# STM32C031 register map
File version: 1.4
CPU: CM0 r0p0, little endian, MPU, FPU, 4 interrupt priority bits
Registers are 32-bit, read-write, reset 0x0 unless marked. A register's access mark holds for its fields unless they carry their own. Offsets are from the block's base; [hi:lo] are bit positions; 'fields as' and 'values as' point back to an identical list.

## TIM16 — General-purpose timers
Base 0x40014400
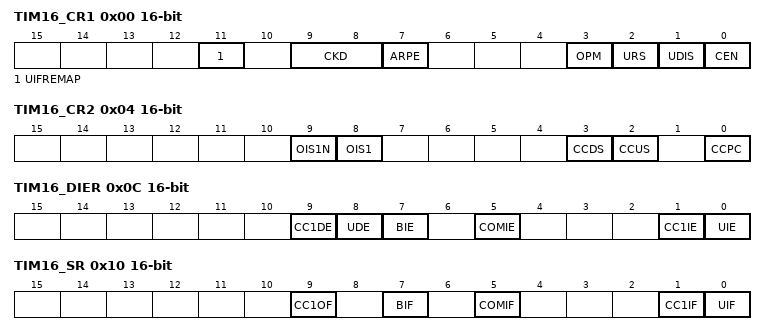
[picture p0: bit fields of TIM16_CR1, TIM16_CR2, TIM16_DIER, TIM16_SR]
0x00 TIM16_CR1 16-bit — TIM16 control register 1
  [11] UIFREMAP — UIF status bit remapping
    0=No remapping. UIF status bit is not copied to TIMx_CNT register bit 31.; 1=Remapping enabled. UIF status bit is copied to TIMx_CNT register bit 31.
  [9:8] CKD — Clock division This bit-field indicates the division ratio between the timer clock (CK_INT) frequency and the dead-time and sampling clock (tDTS)used by the dead-time generators and the digital filters (TIx),
    0=tDTS = tCK_INT; 1=tDTS = 2 * tCK_INT; 2=tDTS = 4 * tCK_INT; 3=Reserved, do not program this value
  [7] ARPE — Auto-reload preload enable
    0=TIMx_ARR register is not buffered; 1=TIMx_ARR register is buffered
  [3] OPM — One pulse mode
    0=Counter is not stopped at update event; 1=Counter stops counting at the next update event (clearing the bit CEN)
  [2] URS — Update request source This bit is set and cleared by software to select the UEV event sources. Counter overflow/underflow Setting the UG bit Update generation through the slave mode controller
    0=Any of the following events generate an update interrupt or DMA request if enabled. These events can be:; 1=Only counter overflow/underflow generates an update interrupt or DMA request if enabled
  [1] UDIS — Update disable This bit is set and cleared by software to enable/disable UEV event generation. Counter overflow/underflow Setting the UG bit Update generation through the slave mode controller Buffered registers are then loaded with their preload values.
    0=UEV enabled. The Update (UEV) event is generated by one of the following events:; 1=UEV disabled. The Update event is not generated, shadow registers keep their value (ARR, PSC, CCRx). However the counter and the prescaler are reinitialized if the UG bit is set or if a hardware reset is received from the slave mode controller.
  [0] CEN — Counter enable Note: External clock and gated mode can work only if the CEN bit has been previously set by software. However trigger mode can set the CEN bit automatically by hardware.
    0=Counter disabled; 1=Counter enabled
0x04 TIM16_CR2 16-bit — TIM16 control register 2
  [9] OIS1N — Output Idle state 1 (OC1N output) Note: This bit can not be modified as long as LOCK level 1, 2 or 3 has been programmed (LOCK bits in TIMx_BDTR register).
    0=OC1N=0 after a dead-time when MOE=0; 1=OC1N=1 after a dead-time when MOE=0
  [8] OIS1 — Output Idle state 1 (OC1 output) Note: This bit can not be modified as long as LOCK level 1, 2 or 3 has been programmed (LOCK bits in TIMx_BDTR register).
    0=OC1=0 (after a dead-time if OC1N is implemented) when MOE=0; 1=OC1=1 (after a dead-time if OC1N is implemented) when MOE=0
  [3] CCDS — Capture/compare DMA selection
    0=CCx DMA request sent when CCx event occurs; 1=CCx DMA requests sent when update event occurs
  [2] CCUS — Capture/compare control update selection Note: This bit acts only on channels that have a complementary output.
    0=When capture/compare control bits are preloaded (CCPC=1), they are updated by setting the COMG bit only; 1=When capture/compare control bits are preloaded (CCPC=1), they are updated by setting the COMG bit or when an rising edge occurs on TRGI
  [0] CCPC — Capture/compare preloaded control Note: This bit acts only on channels that have a complementary output.
    0=CCxE, CCxNE and OCxM bits are not preloaded; 1=CCxE, CCxNE and OCxM bits are preloaded, after having been written, they are updated only when COM bit is set
0x0C TIM16_DIER 16-bit — TIM16 DMA/interrupt enable register
  [9] CC1DE — Capture/Compare 1 DMA request enable
    0=CC1 DMA request disabled; 1=CC1 DMA request enabled
  [8] UDE — Update DMA request enable
    0=Update DMA request disabled; 1=Update DMA request enabled
  [7] BIE — Break interrupt enable
    0=Break interrupt disabled; 1=Break interrupt enabled
  [5] COMIE — COM interrupt enable
    0=COM interrupt disabled; 1=COM interrupt enabled
  [1] CC1IE — Capture/Compare 1 interrupt enable
    0=CC1 interrupt disabled; 1=CC1 interrupt enabled
  [0] UIE — Update interrupt enable
    0=Update interrupt disabled; 1=Update interrupt enabled
0x10 TIM16_SR 16-bit — TIM16 status register
  [9] CC1OF — Capture/Compare 1 overcapture flag This flag is set by hardware only when the corresponding channel is configured in input capture mode. It is cleared by software by writing it to 0.
    0=No overcapture has been detected; 1=The counter value has been captured in TIMx_CCR1 register while CC1IF flag was already set
  [7] BIF — Break interrupt flag This flag is set by hardware as soon as the break input goes active. It can be cleared by software if the break input is not active.
    0=No break event occurred; 1=An active level has been detected on the break input
  [5] COMIF — COM interrupt flag
    0=No COM event occurred; 1=COM interrupt pending
  [1] CC1IF — Capture/Compare 1 interrupt flag This flag is set by hardware. It is cleared by software (input capture or output compare mode) or by reading the TIMx_CCR1 register (input capture mode only). If channel CC1 is configured as output: this flag is set when the content of the counter TIMx_CNT matches the content of the TIMx_CCR1 register. When the content of TIMx_CCR1 is greater than the content of TIMx_ARR, the CC1IF bit goes high on the counter overflow (in up-counting and up/down-counting modes) or underflow (in down-counting mode). There are 3 possible options for flag setting in center-aligned mode, refer to the CMS bits in the TIMx_CR1 register for the full description. If channel CC1 is configured as input: this bit is set when counter value has been captured in TIMx_CCR1 register (an edge has been detected on IC1, as per the edge sensitivity defined with the CC1P and CC1NP bits setting, in TIMx_CCER).
    0=No compare match / No input capture occurred; 1=A compare match or an input capture occurred
  [0] UIF — Update interrupt flag This bit is set by hardware on an update event. It is cleared by software. At overflow regarding the repetition counter value (update if repetition counter = 0) and if the UDIS=0 in the TIMx_CR1 register. When CNT is reinitialized by software using the UG bit in TIMx_EGR register, if URS=0 and UDIS=0 in the TIMx_CR1 register.
    0=No update occurred; 1=Update interrupt pending. This bit is set by hardware when the registers are updated:
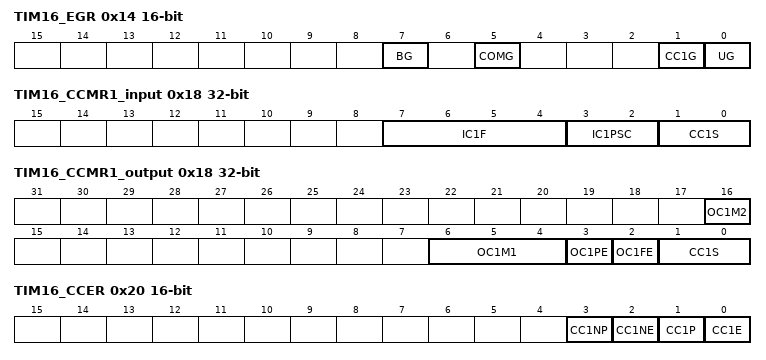
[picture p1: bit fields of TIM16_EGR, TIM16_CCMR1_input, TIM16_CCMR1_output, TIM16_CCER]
0x14 TIM16_EGR 16-bit wo — TIM16 event generation register
  [7] BG — Break generation This bit is set by software in order to generate an event, it is automatically cleared by hardware.
    0=No action; 1=A break event is generated. MOE bit is cleared and BIF flag is set. Related interrupt or DMA transfer can occur if enabled.
  [5] COMG — Capture/Compare control update generation This bit can be set by software, it is automatically cleared by hardware. Note: This bit acts only on channels that have a complementary output.
    0=No action; 1=When the CCPC bit is set, it is possible to update the CCxE, CCxNE and OCxM bits
  [1] CC1G — Capture/Compare 1 generation This bit is set by software in order to generate an event, it is automatically cleared by hardware. If channel CC1 is configured as output: CC1IF flag is set, Corresponding interrupt or DMA request is sent if enabled. If channel CC1 is configured as input: The current value of the counter is captured in TIMx_CCR1 register. The CC1IF flag is set, the corresponding interrupt or DMA request is sent if enabled. The CC1OF flag is set if the CC1IF flag was already high.
    0=No action; 1=A capture/compare event is generated on channel 1:
  [0] UG — Update generation This bit can be set by software, it is automatically cleared by hardware.
    0=No action; 1=Reinitialize the counter and generates an update of the registers. Note that the prescaler counter is cleared too (anyway the prescaler ratio is not affected).
0x18 TIM16_CCMR1_input — TIM16 capture/compare mode register 1 [alternate]
  [7:4] IC1F — Input capture 1 filter This bit-field defines the frequency used to sample TI1 input and the length of the digital filter applied to TI1. The digital filter is made of an event counter in which N consecutive events are needed to validate a transition on the output:
    0=No filter, sampling is done at fDTS; 1=fSAMPLING=fCK_INT, N=2; 2=fSAMPLING=fCK_INT, N=4; 3=fSAMPLING=fCK_INT, N=8; 4=fSAMPLING=fDTS/2, N=; 5=fSAMPLING=fDTS/2, N=8; 6=fSAMPLING=fDTS/4, N=6; 7=fSAMPLING=fDTS/4, N=8; 8=fSAMPLING=fDTS/8, N=6; 9=fSAMPLING=fDTS/8, N=8; 10=fSAMPLING=fDTS/16, N=5; 11=fSAMPLING=fDTS/16, N=6; 12=fSAMPLING=fDTS/16, N=8; 13=fSAMPLING=fDTS/32, N=5; 14=fSAMPLING=fDTS/32, N=6; 15=fSAMPLING=fDTS/32, N=8
  [3:2] IC1PSC — Input capture 1 prescaler This bit-field defines the ratio of the prescaler acting on CC1 input (IC1). The prescaler is reset as soon as CC1E=0 (TIMx_CCER register).
    0=no prescaler, capture is done each time an edge is detected on the capture input; 1=capture is done once every 2 events; 2=capture is done once every 4 events; 3=capture is done once every 8 events
  [1:0] CC1S — Capture/Compare 1 Selection This bit-field defines the direction of the channel (input/output) as well as the used input. Others: Reserved Note: CC1S bits are writable only when the channel is OFF (CC1E = 0 in TIMx_CCER).
    0=CC1 channel is configured as output; 1=CC1 channel is configured as input, IC1 is mapped on TI1
0x18 TIM16_CCMR1_output (alternate view of TIM16_CCMR1_input) — TIM16 capture/compare mode register 1 [alternate]
  [16] OC1M2 — Output Compare 1 mode These bits define the behavior of the output reference signal OC1REF from which OC1 and OC1N are derived. OC1REF is active high whereas OC1 and OC1N active level depends on CC1P and CC1NP bits. All other values: Reserved Note: These bits can not be modified as long as LOCK level 3 has been programmed (LOCK bits in TIMx_BDTR register) and CC1S=00 (the channel is configured in output). In PWM mode 1 or 2, the OCREF level changes only when the result of the comparison changes or when the output compare mode switches from frozen mode to PWM mode. The OC1M[3] bit is not contiguous, located in bit 16.
  [6:4] OC1M1 — Output Compare 1 mode These bits define the behavior of the output reference signal OC1REF from which OC1 and OC1N are derived. OC1REF is active high whereas OC1 and OC1N active level depends on CC1P and CC1NP bits. All other values: Reserved Note: These bits can not be modified as long as LOCK level 3 has been programmed (LOCK bits in TIMx_BDTR register) and CC1S=00 (the channel is configured in output). In PWM mode 1 or 2, the OCREF level changes only when the result of the comparison changes or when the output compare mode switches from frozen mode to PWM mode. The OC1M[3] bit is not contiguous, located in bit 16.
  [3] OC1PE — Output Compare 1 preload enable Note: These bits can not be modified as long as LOCK level 3 has been programmed (LOCK bits in TIMx_BDTR register) and CC1S=00 (the channel is configured in output). The PWM mode can be used without validating the preload register only in one pulse mode (OPM bit set in TIMx_CR1 register). Else the behavior is not guaranteed.
    0=Preload register on TIMx_CCR1 disabled. TIMx_CCR1 can be written at anytime, the new value is taken in account immediately.; 1=Preload register on TIMx_CCR1 enabled. Read/Write operations access the preload register. TIMx_CCR1 preload value is loaded in the active register at each update event.
  [2] OC1FE — Output Compare 1 fast enable This bit decreases the latency between a trigger event and a transition on the timer output. It must be used in one-pulse mode (OPM bit set in TIMx_CR1 register), to have the output pulse starting as soon as possible after the starting trigger.
    0=CC1 behaves normally depending on counter and CCR1 values even when the trigger is ON. The minimum delay to activate CC1 output when an edge occurs on the trigger input is 5 clock cycles.; 1=An active edge on the trigger input acts like a compare match on CC1 output. Then, OC is set to the compare level independently of the result of the comparison. Delay to sample the trigger input and to activate CC1 output is reduced to 3 clock cycles. OC1FE acts only if the channel is configured in PWM1 or PWM2 mode.
  [1:0] CC1S — Capture/Compare 1 selection This bit-field defines the direction of the channel (input/output) as well as the used input. Others: Reserved Note: CC1S bits are writable only when the channel is OFF (CC1E = 0 in TIMx_CCER).
    values as TIM16_CCMR1_input.CC1S
0x20 TIM16_CCER 16-bit — TIM16 capture/compare enable register
  [3] CC1NP — Capture/Compare 1 complementary output polarity CC1 channel configured as output: CC1 channel configured as input: This bit is used in conjunction with CC1P to define the polarity of TI1FP1 and TI2FP1. Refer to the description of CC1P. Note: This bit is not writable as soon as LOCK level 2 or 3 has been programmed (LOCK bits in TIMx_BDTR register) and CC1S=00 (the channel is configured in output). On channels that have a complementary output, this bit is preloaded. If the CCPC bit is set in the TIMx_CR2 register then the CC1NP active bit takes the new value from the preloaded bit only when a commutation event is generated.
    0=OC1N active high; 1=OC1N active low
  [2] CC1NE — Capture/Compare 1 complementary output enable
    0=Off - OC1N is not active. OC1N level is then function of MOE, OSSI, OSSR, OIS1, OIS1N and CC1E bits.; 1=On - OC1N signal is output on the corresponding output pin depending on MOE, OSSI, OSSR, OIS1, OIS1N and CC1E bits
  [1] CC1P — Capture/Compare 1 output polarity When CC1 channel is configured as input, both CC1NP/CC1P bits select the active polarity of TI1FP1 and TI2FP1 for trigger or capture operations. CC1NP=0, CC1P=0: non-inverted/rising edge. The circuit is sensitive to TIxFP1 rising edge (capture or trigger operations in reset, external clock or trigger mode), TIxFP1 is not inverted (trigger operation in gated mode or encoder mode). CC1NP=0, CC1P=1: inverted/falling edge. The circuit is sensitive to TIxFP1 falling edge (capture or trigger operations in reset, external clock or trigger mode), TIxFP1 is inverted (trigger operation in gated mode or encoder mode). CC1NP=1, CC1P=1: non-inverted/both edges/ The circuit is sensitive to both TIxFP1 rising and falling edges (capture or trigger operations in reset, external clock or trigger mode), TIxFP1is not inverted (trigger operation in gated mode). This configuration must not be used in encoder mode. CC1NP=1, CC1P=0: this configuration is reserved, it must not be used. Note: This bit is not writable as soon as LOCK level 2 or 3 has been programmed (LOCK bits in TIMx_BDTR register). On channels that have a complementary output, this bit is preloaded. If the CCPC bit is set in the TIMx_CR2 register then the CC1P active bit takes the new value from the preloaded bit only when a Commutation event is generated.
    0=OC1 active high (output mode) / Edge sensitivity selection (input mode, see below); 1=OC1 active low (output mode) / Edge sensitivity selection (input mode, see below)
  [0] CC1E — Capture/Compare 1 output enable When CC1 channel is configured as output, the OC1 level depends on MOE, OSSI, OSSR, OIS1, OIS1N and CC1NE bits, regardless of the CC1E bits state. Refer to for details.
    0=Capture mode disabled / OC1 is not active (see below); 1=Capture mode enabled / OC1 signal is output on the corresponding output pin
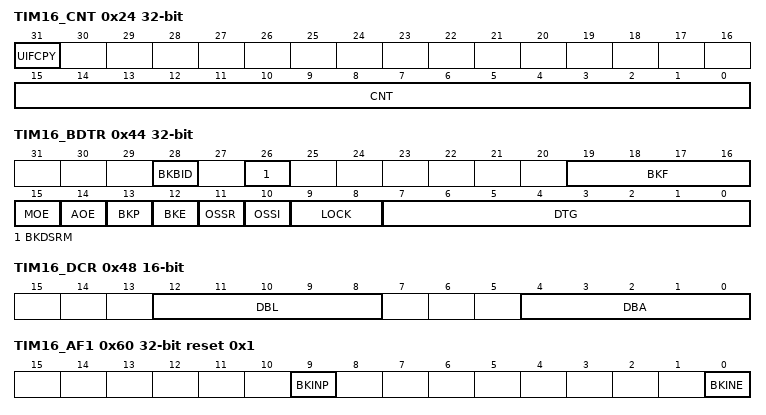
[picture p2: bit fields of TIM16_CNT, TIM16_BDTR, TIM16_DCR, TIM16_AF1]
0x24 TIM16_CNT access per field — TIM16 counter
  [31] UIFCPY ro — UIF Copy This bit is a read-only copy of the UIF bit of the TIMx_ISR register. If the UIFREMAP bit in TIMx_CR1 is reset, bit 31 is reserved and read as 0.
  [15:0] CNT rw — Counter value
0x28 TIM16_PSC 16-bit — TIM16 prescaler
  [15:0] PSC — Prescaler value The counter clock frequency (CK_CNT) is equal to fCK_PSC / (PSC[15:0] + 1). PSC contains the value to be loaded in the active prescaler register at each update event (including when the counter is cleared through UG bit of TIMx_EGR register or through trigger controller when configured in reset mode).
0x2C TIM16_ARR 16-bit reset 0xFFFF — TIM16 auto-reload register
  [15:0] ARR — Auto-reload value ARR is the value to be loaded in the actual auto-reload register. Refer to the for more details about ARR update and behavior. The counter is blocked while the auto-reload value is null.
0x30 TIM16_RCR 16-bit — TIM16 repetition counter register
  [7:0] REP — Repetition counter value These bits allow the user to set-up the update rate of the compare registers (i.e. periodic transfers from preload to active registers) when preload registers are enable, as well as the update interrupt generation rate, if this interrupt is enable. Each time the REP_CNT related downcounter reaches zero, an update event is generated and it restarts counting from REP value. As REP_CNT is reloaded with REP value only at the repetition update event U_RC, any write to the TIMx_RCR register is not taken in account until the next repetition update event. It means in PWM mode (REP+1) corresponds to the number of PWM periods in edge-aligned mode.
0x34 TIM16_CCR1 16-bit — TIM16 capture/compare register 1
  [15:0] CCR1 — Capture/Compare 1 value If channel CC1 is configured as output: CCR1 is the value to be loaded in the actual capture/compare 1 register (preload value). It is loaded permanently if the preload feature is not selected in the TIMx_CCMR1 register (bit OC1PE). Else the preload value is copied in the active capture/compare 1 register when an update event occurs. The active capture/compare register contains the value to be compared to the counter TIMx_CNT and signaled on OC1 output. If channel CC1 is configured as input: CCR1 is the counter value transferred by the last input capture 1 event (IC1).
0x44 TIM16_BDTR — TIM16 break and dead-time register
  [28] BKBID — Break Bidirectional In the bidirectional mode (BKBID bit set to 1), the break input is configured both in input mode and in open drain output mode. Any active break event asserts a low logic level on the Break input to indicate an internal break event to external devices. Note: This bit cannot be modified as long as LOCK level 1 has been programmed (LOCK bits in TIMx_BDTR register). Note: Any write operation to this bit takes a delay of 1 APB clock cycle to become effective.
    0=Break input BRK in input mode; 1=Break input BRK in bidirectional mode
  [26] BKDSRM — Break Disarm This bit is cleared by hardware when no break source is active. The BKDSRM bit must be set by software to release the bidirectional output control (open-drain output in Hi-Z state) and then be polled it until it is reset by hardware, indicating that the fault condition has disappeared. Note: Any write operation to this bit takes a delay of 1 APB clock cycle to become effective.
    0=Break input BRK is armed; 1=Break input BRK is disarmed
  [19:16] BKF — Break filter This bit-field defines the frequency used to sample BRK input and the length of the digital filter applied to BRK. The digital filter is made of an event counter in which N events are needed to validate a transition on the output: This bit cannot be modified when LOCK level 1 has been programmed (LOCK bits in TIMx_BDTR register).
    0=No filter, BRK acts asynchronously; 1=fSAMPLING=fCK_INT, N=2; 2=fSAMPLING=fCK_INT, N=4; 3=fSAMPLING=fCK_INT, N=8; 4=fSAMPLING=fDTS/2, N=6; 5=fSAMPLING=fDTS/2, N=8; 6=fSAMPLING=fDTS/4, N=6; 7=fSAMPLING=fDTS/4, N=8; 8=fSAMPLING=fDTS/8, N=6; 9=fSAMPLING=fDTS/8, N=8; 10=fSAMPLING=fDTS/16, N=5; 11=fSAMPLING=fDTS/16, N=6; 12=fSAMPLING=fDTS/16, N=8; 13=fSAMPLING=fDTS/32, N=5; 14=fSAMPLING=fDTS/32, N=6; 15=fSAMPLING=fDTS/32, N=8
  [15] MOE — Main output enable This bit is cleared asynchronously by hardware as soon as the break input is active. It is set by software or automatically depending on the AOE bit. It is acting only on the channels which are configured in output. enable register (TIM16_CCER)(TIMx_CCER)(x = 16 to 17) on page 1793).
    0=OC and OCN outputs are disabled or forced to idle state depending on the OSSI bit; 1=OC and OCN outputs are enabled if their respective enable bits are set (CCxE, CCxNE in TIMx_CCER register)See OC/OCN enable description for more details (
  [14] AOE — Automatic output enable Note: This bit can not be modified as long as LOCK level 1 has been programmed (LOCK bits in TIMx_BDTR register).
    0=MOE can be set only by software; 1=MOE can be set by software or automatically at the next update event (if the break input is not be active)
  [13] BKP — Break polarity Note: This bit can not be modified as long as LOCK level 1 has been programmed (LOCK bits in TIMx_BDTR register). Any write operation to this bit takes a delay of 1 APB clock cycle to become effective.
    0=Break input BRK is active low; 1=Break input BRK is active high
  [12] BKE — Break enable 1; Break inputs (BRK and CCS clock failure event) enabled Note: This bit cannot be modified when LOCK level 1 has been programmed (LOCK bits in TIMx_BDTR register). Any write operation to this bit takes a delay of 1 APB clock cycle to become effective.
    0=Break inputs (BRK and CCS clock failure event) disabled
  [11] OSSR — Off-state selection for Run mode This bit is used when MOE=1 on channels that have a complementary output which are configured as outputs. OSSR is not implemented if no complementary output is implemented in the timer. See OC/OCN enable description for more details (enable register (TIM16_CCER)(TIMx_CCER)(x = 16 to 17) on page 1793). Note: This bit can not be modified as soon as the LOCK level 2 has been programmed (LOCK bits in TIMx_BDTR register).
    0=When inactive, OC/OCN outputs are disabled (the timer releases the output control which is taken over by the GPIO, which forces a Hi-Z state); 1=When inactive, OC/OCN outputs are enabled with their inactive level as soon as CCxE=1 or CCxNE=1 (the output is still controlled by the timer)
  [10] OSSI — Off-state selection for Idle mode This bit is used when MOE=0 on channels configured as outputs. See OC/OCN enable description for more details (enable register (TIM16_CCER)(TIMx_CCER)(x = 16 to 17) on page 1793). Note: This bit can not be modified as soon as the LOCK level 2 has been programmed (LOCK bits in TIMx_BDTR register).
    0=When inactive, OC/OCN outputs are disabled (OC/OCN enable output signal=0); 1=When inactive, OC/OCN outputs are forced first with their idle level as soon as CCxE=1 or CCxNE=1. OC/OCN enable output signal=1)
  [9:8] LOCK — Lock configuration These bits offer a write protection against software errors. Note: The LOCK bits can be written only once after the reset. Once the TIMx_BDTR register has been written, their content is frozen until the next reset.
    0=LOCK OFF - No bit is write protected; 1=LOCK Level 1 = DTG bits in TIMx_BDTR register, OISx and OISxN bits in TIMx_CR2 register and BKE/BKP/AOE bits in TIMx_BDTR register can no longer be written; 2=LOCK Level 2 = LOCK Level 1 + CC Polarity bits (CCxP/CCxNP bits in TIMx_CCER register, as long as the related channel is configured in output through the CCxS bits) as well as OSSR and OSSI bits can no longer be written; 3=LOCK Level 3 = LOCK Level 2 + CC Control bits (OCxM and OCxPE bits in TIMx_CCMRx registers, as long as the related channel is configured in output through the CCxS bits) can no longer be written
  [7:0] DTG — Dead-time generator setup
0x48 TIM16_DCR 16-bit — TIM16 DMA control register
  [12:8] DBL — DMA burst length This 5-bit field defines the length of DMA transfers (the timer recognizes a burst transfer when a read or a write access is done to the TIMx_DMAR address), i.e. the number of transfers. Transfers can be in half-words or in bytes (see example below). ...
    0=1 transfer,; 1=2 transfers,; 2=3 transfers,; 17=18 transfers
  [4:0] DBA — DMA base address This 5-bit field defines the base-address for DMA transfers (when read/write access are done through the TIMx_DMAR address). DBA is defined as an offset starting from the address of the TIMx_CR1 register. Example: ... Example: Let us consider the following transfer: DBL = 7 transfers and DBA = TIMx_CR1. In this case the transfer is done to/from 7 registers starting from the TIMx_CR1 address.
    0=TIMx_CR1,; 1=TIMx_CR2,; 2=TIMx_SMCR,
0x4C TIM16_DMAR 16-bit — TIM16 DMA address for full transfer
  [15:0] DMAB — DMA register for burst accesses A read or write operation to the DMAR register accesses the register located at the address (TIMx_CR1 address) + (DBA + DMA index) x 4 where TIMx_CR1 address is the address of the control register 1, DBA is the DMA base address configured in TIMx_DCR register, DMA index is automatically controlled by the DMA transfer, and ranges from 0 to DBL (DBL configured in TIMx_DCR).
0x60 TIM16_AF1 reset 0x1 — TIM16 alternate function register 1
  [9] BKINP — BRK BKIN input polarity This bit selects the BKIN alternate function input sensitivity. It must be programmed together with the BKP polarity bit. Note: This bit can not be modified as long as LOCK level 1 has been programmed (LOCK bits in TIMx_BDTR register).
    0=BKIN input is active low; 1=BKIN input is active high
  [0] BKINE — BRK BKIN input enable This bit enables the BKIN alternate function input for the timers BRK input. BKIN input is ORed with the other BRK sources. Note: This bit can not be modified as long as LOCK level 1 has been programmed (LOCK bits in TIMx_BDTR register).
    0=BKIN input disabled; 1=BKIN input enabled
0x68 TIM16_TISEL — TIM16 input selection register
  [3:0] TI1SEL — selects TI1[0] to TI1[15] input Others: Reserved
    0=TIM16_CH1 input; 1=LSI; 2=LSE; 4=MCO2

## TIM17 — General-purpose timers
Base 0x40014800
Registers as TIM16 (with TIM16 read as TIM17); these are added or differ:
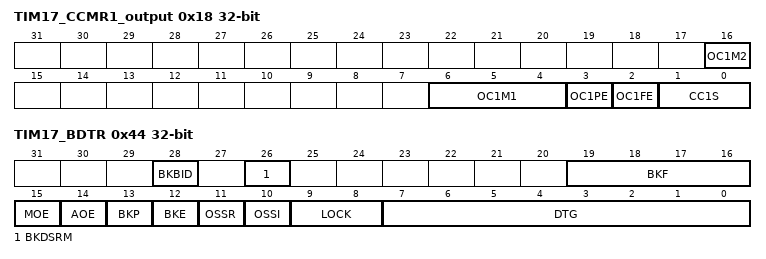
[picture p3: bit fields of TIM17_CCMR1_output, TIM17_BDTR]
0x18 TIM17_CCMR1_output (alternate view of TIM17_CCMR1_input) — TIM17 capture/compare mode register 1 [alternate]
  [16] OC1M2 — Output Compare 1 mode These bits define the behavior of the output reference signal OC1REF from which OC1 and OC1N are derived. OC1REF is active high whereas OC1 and OC1N active level depends on CC1P and CC1NP bits. All other values: Reserved Note: These bits can not be modified as long as LOCK level 3 has been programmed (LOCK bits in TIMx_BDTR register) and CC1S=00 (the channel is configured in output). In PWM mode 1 or 2, the OCREF level changes only when the result of the comparison changes or when the output compare mode switches from frozen mode to PWM mode. The OC1M[3] bit is not contiguous, located in bit 16.
    0=Frozen - The comparison between the output compare register TIMx_CCR1 and the counter TIMx_CNT has no effect on the outputs; 1=Set channel 1 to active level on match. OC1REF signal is forced high when the counter TIMx_CNT matches the capture/compare register 1 (TIMx_CCR1).
  [6:4] OC1M1 — Output Compare 1 mode These bits define the behavior of the output reference signal OC1REF from which OC1 and OC1N are derived. OC1REF is active high whereas OC1 and OC1N active level depends on CC1P and CC1NP bits. All other values: Reserved Note: These bits can not be modified as long as LOCK level 3 has been programmed (LOCK bits in TIMx_BDTR register) and CC1S=00 (the channel is configured in output). In PWM mode 1 or 2, the OCREF level changes only when the result of the comparison changes or when the output compare mode switches from frozen mode to PWM mode. The OC1M[3] bit is not contiguous, located in bit 16.
    0=Frozen - The comparison between the output compare register TIMx_CCR1 and the counter TIMx_CNT has no effect on the outputs; 1=Set channel 1 to active level on match. OC1REF signal is forced high when the counter TIMx_CNT matches the capture/compare register 1 (TIMx_CCR1).; 2=Set channel 1 to inactive level on match. OC1REF signal is forced low when the counter TIMx_CNT matches the capture/compare register 1 (TIMx_CCR1).; 3=Toggle - OC1REF toggles when TIMx_CNT=TIMx_CCR1; 4=Force inactive level - OC1REF is forced low; 5=Force active level - OC1REF is forced high; 6=PWM mode 1 - Channel 1 is active as long as TIMx_CNT<TIMx_CCR1 else inactive; 7=PWM mode 2 - Channel 1 is inactive as long as TIMx_CNT<TIMx_CCR1 else active
  [3] OC1PE — Output Compare 1 preload enable Note: These bits can not be modified as long as LOCK level 3 has been programmed (LOCK bits in TIMx_BDTR register) and CC1S=00 (the channel is configured in output). The PWM mode can be used without validating the preload register only in one pulse mode (OPM bit set in TIMx_CR1 register). Else the behavior is not guaranteed.
    values as TIM16.TIM16_CCMR1_output.OC1PE
  [2] OC1FE — Output Compare 1 fast enable This bit decreases the latency between a trigger event and a transition on the timer output. It must be used in one-pulse mode (OPM bit set in TIMx_CR1 register), to have the output pulse starting as soon as possible after the starting trigger.
    values as TIM16.TIM16_CCMR1_output.OC1FE
  [1:0] CC1S — Capture/Compare 1 selection This bit-field defines the direction of the channel (input/output) as well as the used input. Others: Reserved Note: CC1S bits are writable only when the channel is OFF (CC1E = 0 in TIMx_CCER).
    0=CC1 channel is configured as output; 1=CC1 channel is configured as input, IC1 is mapped on TI1
0x44 TIM17_BDTR — TIM17 break and dead-time register
  fields as TIM16.TIM16_BDTR
0x68 TIM17_TISEL — TIM17 input selection register
  [3:0] TI1SEL — selects TI1[0] to TI1[15] input Others: Reserved
    0=TIM17_CH1 input; 2=HSE/32; 3=MCO; 4=MCO2
